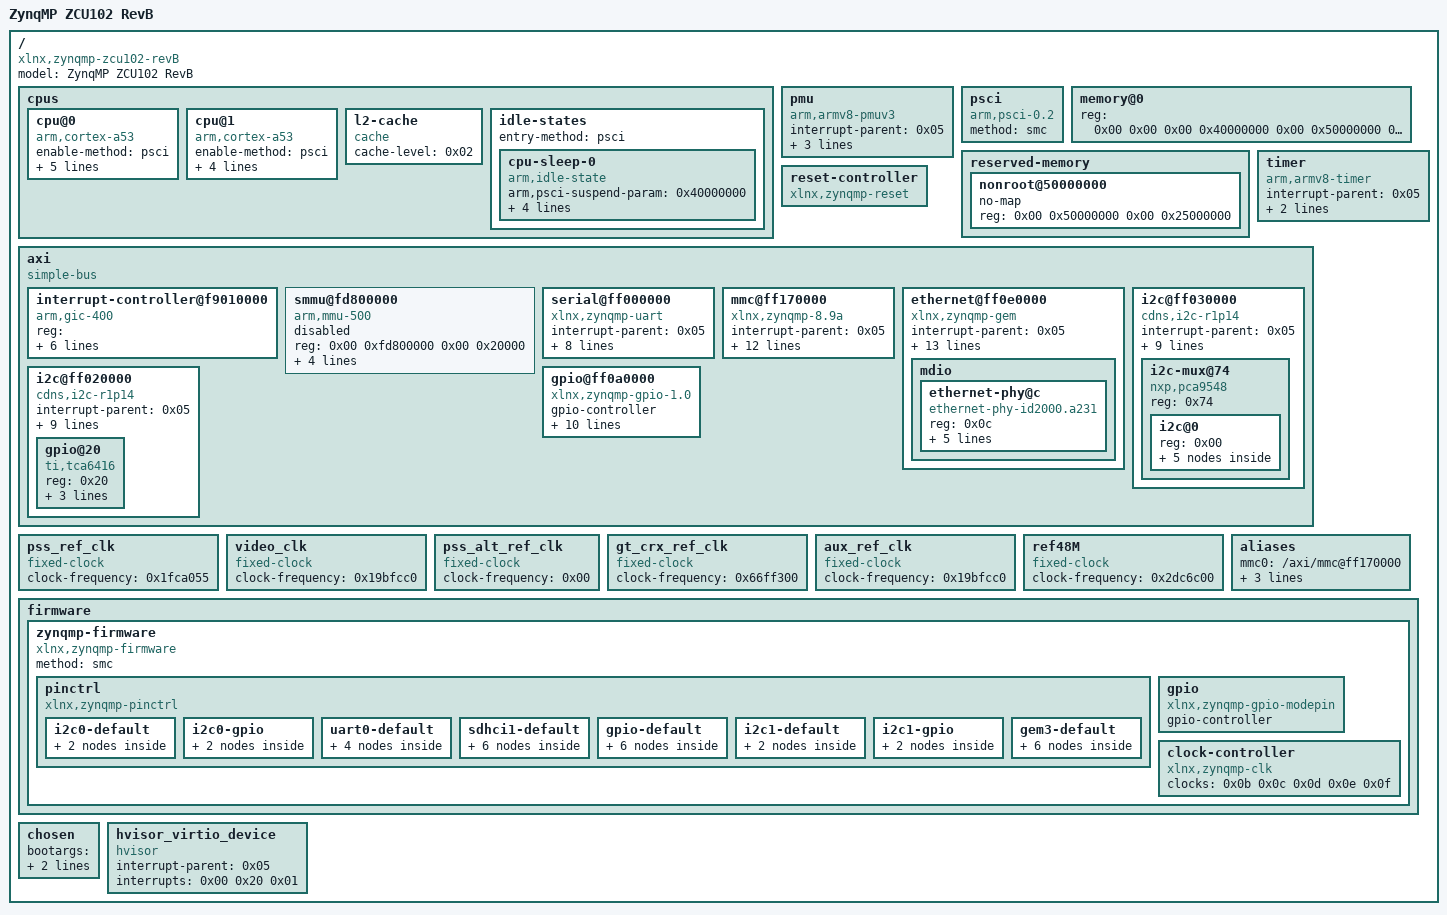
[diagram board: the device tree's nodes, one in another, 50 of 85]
/dts-v1/;

/ {
	compatible = "xlnx,zynqmp-zcu102-revB\0xlnx,zynqmp-zcu102\0xlnx,zynqmp";
	#address-cells = <0x02>;
	#size-cells = <0x02>;
	model = "ZynqMP ZCU102 RevB";

    cpus {
		#address-cells = <0x01>;
		#size-cells = <0x00>;

		cpu@0 {
			compatible = "arm,cortex-a53";
			device_type = "cpu";
			enable-method = "psci";
			operating-points-v2 = <0x01>;
			reg = <0x00>;
			cpu-idle-states = <0x02>;
			next-level-cache = <0x03>;
			clocks = <0x04 0x0a>;
			phandle = <0x06>;
		};

		cpu@1 {
			compatible = "arm,cortex-a53";
			device_type = "cpu";
			enable-method = "psci";
			reg = <0x01>;
			operating-points-v2 = <0x01>;
			cpu-idle-states = <0x02>;
			next-level-cache = <0x03>;
			phandle = <0x07>;
		};

		l2-cache {
			compatible = "cache";
			cache-level = <0x02>;
			phandle = <0x03>;
		};

		idle-states {
			entry-method = "psci";

			cpu-sleep-0 {
				compatible = "arm,idle-state";
				arm,psci-suspend-param = <0x40000000>;
				local-timer-stop;
				entry-latency-us = <0x12c>;
				exit-latency-us = <0x258>;
				min-residency-us = <0x2710>;
				phandle = <0x02>;
			};
		};
	};

	pmu {
		compatible = "arm,armv8-pmuv3";
		interrupt-parent = <0x05>;
		interrupts = <0x00 0x8f 0x04 0x00 0x90 0x04 0x00 0x91 0x04 0x00 0x92 0x04>;
		interrupt-affinity = <0x06 0x07 0x08 0x09>;
	};

	psci {
		compatible = "arm,psci-0.2";
		method = "smc";
	};

    memory@0 {
		device_type = "memory";
		reg = <0x00 0x00 0x00 0x40000000 0x00 0x50000000 0x00 0x25000000>;
	};

	reserved-memory {
		#address-cells = <0x02>;
		#size-cells = <0x02>;
		ranges;
		nonroot@50000000 {
			no-map;
			reg = <0x00 0x50000000 0x00 0x25000000>;
		};
	};

    timer {
		compatible = "arm,armv8-timer";
		interrupt-parent = <0x05>;
		interrupts = <0x01 0x0d 0xf08 0x01 0x0e 0xf08 0x01 0x0b 0xf08 0x01 0x0a 0xf08>;
	};

    reset-controller {
			compatible = "xlnx,zynqmp-reset";
			#reset-cells = <0x01>;
			phandle = <0x11>;
	};


    axi {
		compatible = "simple-bus";
		bootph-all;
		#address-cells = <0x02>;
		#size-cells = <0x02>;
		ranges;
		phandle = <0x58>;

		interrupt-controller@f9010000 {
			compatible = "arm,gic-400";
			#interrupt-cells = <0x03>;
			reg = <0x00 0xf9010000 0x00 0x10000 0x00 0xf9020000 0x00 0x20000 0x00 0xf9040000 0x00 0x20000 0x00 0xf9060000 0x00 0x20000>;
			interrupt-controller;
			interrupt-parent = <0x05>;
			interrupts = <0x01 0x09 0xf04>;
			num_cpus = <0x02>;
			num_interrupts = <0x60>;
			phandle = <0x05>;
		};

		smmu@fd800000 {
			compatible = "arm,mmu-500";
			reg = <0x00 0xfd800000 0x00 0x20000>;
			#iommu-cells = <0x01>;
			status = "disabled";
			#global-interrupts = <0x01>;
			interrupt-parent = <0x05>;
			interrupts = <0x00 0x9b 0x04 0x00 0x9b 0x04 0x00 0x9b 0x04 0x00 0x9b 0x04 0x00 0x9b 0x04 0x00 0x9b 0x04 0x00 0x9b 0x04 0x00 0x9b 0x04 0x00 0x9b 0x04 0x00 0x9b 0x04 0x00 0x9b 0x04 0x00 0x9b 0x04 0x00 0x9b 0x04 0x00 0x9b 0x04 0x00 0x9b 0x04 0x00 0x9b 0x04 0x00 0x9b 0x04>;
			phandle = <0x14>;
		};


        serial@ff000000 {
			bootph-all;
			compatible = "xlnx,zynqmp-uart\0cdns,uart-r1p12";
			status = "okay";
			interrupt-parent = <0x05>;
			interrupts = <0x00 0x15 0x04>;
			reg = <0x00 0xff000000 0x00 0x1000>;
			clock-names = "uart_clk\0pclk";
			power-domains = <0x12 0x21>;
			clocks = <0x04 0x38 0x04 0x1f>;
			pinctrl-names = "default";
			pinctrl-0 = <0x25>;
			cts-override;
			device_type = "serial";
			port-number = <0x00>;
			u-boot,dm-pre-reloc;
			phandle = <0x95>;
		};


        mmc@ff170000 {
			bootph-all;
			compatible = "xlnx,zynqmp-8.9a\0arasan,sdhci-8.9a";
			status = "okay";
			interrupt-parent = <0x05>;
			interrupts = <0x00 0x31 0x04>;
			reg = <0x00 0xff170000 0x00 0x1000>;
			clock-names = "clk_xin\0clk_ahb";
			iommus = <0x14 0x871>;
			power-domains = <0x12 0x28>;
			#clock-cells = <0x01>;
			clock-output-names = "clk_out_sd1\0clk_in_sd1";
			resets = <0x11 0x27>;
			clocks = <0x04 0x37 0x04 0x1f>;
			assigned-clocks = <0x04 0x37>;
			no-1-8-v;
			pinctrl-names = "default";
			pinctrl-0 = <0x24>;
			clock-frequency = <0xa98a581>;
			xlnx,mio-bank = <0x01>;
			phandle = <0x8e>;
		};

		ethernet@ff0e0000 {
			compatible = "xlnx,zynqmp-gem\0cdns,gem";
			status = "okay";
			interrupt-parent = <0x05>;
			interrupts = <0x00 0x3f 0x04 0x00 0x3f 0x04>;
			reg = <0x00 0xff0e0000 0x00 0x1000>;
			clock-names = "pclk\0hclk\0tx_clk\0rx_clk\0tsu_clk";
			#address-cells = <0x01>;
			#size-cells = <0x00>;
			iommus = <0x14 0x877>;
			power-domains = <0x12 0x20>;
			resets = <0x11 0x20>;
			reset-names = "gem3_rst";
			clocks = <0x04 0x1f 0x04 0x6b 0x04 0x30 0x04 0x34 0x04 0x2c>;
			assigned-clocks = <0x04 0x2c>;
			phy-handle = <0x15>;
			pinctrl-names = "default";
			pinctrl-0 = <0x16>;
			phy-mode = "rgmii-id";
			xlnx,ptp-enet-clock = <0x00>;
			local-mac-address = [ff ff ff ff ff ff];
			phandle = <0x74>;

			mdio {
				#address-cells = <0x01>;
				#size-cells = <0x00>;
				phandle = <0x75>;

				ethernet-phy@c {
					#phy-cells = <0x01>;
					compatible = "ethernet-phy-id2000.a231";
					reg = <0x0c>;
					ti,rx-internal-delay = <0x08>;
					ti,tx-internal-delay = <0x0a>;
					ti,fifo-depth = <0x01>;
					ti,dp83867-rxctrl-strap-quirk;
					reset-gpios = <0x17 0x06 0x01>;
					phandle = <0x15>;
				};
			};
		};
		

		i2c@ff030000 {
			compatible = "cdns,i2c-r1p14";
			status = "okay";
			interrupt-parent = <0x05>;
			interrupts = <0x00 0x12 0x04>;
			clock-frequency = <0x61a80>;
			reg = <0x00 0xff030000 0x00 0x1000>;
			#address-cells = <0x01>;
			#size-cells = <0x00>;
			power-domains = <0x12 0x26>;
			clocks = <0x04 0x3e>;
			pinctrl-names = "default\0gpio";
			pinctrl-0 = <0x1c>;
			pinctrl-1 = <0x1d>;
			scl-gpios = <0x1b 0x10 0x06>;
			sda-gpios = <0x1b 0x11 0x06>;
			phandle = <0x78>;

			i2c-mux@74 {
				compatible = "nxp,pca9548";
				#address-cells = <0x01>;
				#size-cells = <0x00>;
				reg = <0x74>;

				i2c@0 {
					#address-cells = <0x01>;
					#size-cells = <0x00>;
					reg = <0x00>;

					eeprom@54 {
						compatible = "atmel,24c08";
						reg = <0x54>;
						#address-cells = <0x01>;
						#size-cells = <0x01>;
						phandle = <0x79>;

						board-sn@0 {
							reg = <0x00 0x14>;
							phandle = <0x7a>;
						};

						eth-mac@20 {
							reg = <0x20 0x06>;
							phandle = <0x7b>;
						};

						board-name@d0 {
							reg = <0xd0 0x06>;
							phandle = <0x7c>;
						};

						board-revision@e0 {
							reg = <0xe0 0x03>;
							phandle = <0x7d>;
						};
					};
				};
			};
		};


		i2c@ff020000 {
			compatible = "cdns,i2c-r1p14";
			status = "okay";
			interrupt-parent = <0x05>;
			interrupts = <0x00 0x11 0x04>;
			clock-frequency = <0x61a80>;
			reg = <0x00 0xff020000 0x00 0x1000>;
			#address-cells = <0x01>;
			#size-cells = <0x00>;
			power-domains = <0x12 0x25>;
			clocks = <0x04 0x3d>;
			pinctrl-names = "default\0gpio";
			pinctrl-0 = <0x19>;
			pinctrl-1 = <0x1a>;
			scl-gpios = <0x1b 0x0e 0x06>;
			sda-gpios = <0x1b 0x0f 0x06>;
			phandle = <0x76>;

			gpio@20 {
				compatible = "ti,tca6416";
				reg = <0x20>;
				gpio-controller;
				#gpio-cells = <0x02>;
				gpio-line-names = "PS_GTR_LAN_SEL0\0PS_GTR_LAN_SEL1\0PS_GTR_LAN_SEL2\0PS_GTR_LAN_SEL3\0PCI_CLK_DIR_SEL\0IIC_MUX_RESET_B\0GEM3_EXP_RESET_B\0\0\0\0\0\0\0\0\0";
				phandle = <0x17>;
			};
		};


		gpio@ff0a0000 {
			compatible = "xlnx,zynqmp-gpio-1.0";
			status = "okay";
			#gpio-cells = <0x02>;
			gpio-controller;
			interrupt-parent = <0x05>;
			interrupts = <0x00 0x10 0x04>;
			interrupt-controller;
			#interrupt-cells = <0x02>;
			reg = <0x00 0xff0a0000 0x00 0x1000>;
			power-domains = <0x12 0x2e>;
			clocks = <0x04 0x1f>;
			pinctrl-names = "default";
			pinctrl-0 = <0x18>;
			emio-gpio-width = <0x20>;
			gpio-mask-high = <0x00>;
			gpio-mask-low = <0x5600>;
			phandle = <0x1b>;
		};
    };

    pss_ref_clk {
		bootph-all;
		compatible = "fixed-clock";
		#clock-cells = <0x00>;
		clock-frequency = <0x1fca055>;
		phandle = <0x0b>;
	};

	video_clk {
		bootph-all;
		compatible = "fixed-clock";
		#clock-cells = <0x00>;
		clock-frequency = <0x19bfcc0>;
		phandle = <0x0c>;
	};

	pss_alt_ref_clk {
		bootph-all;
		compatible = "fixed-clock";
		#clock-cells = <0x00>;
		clock-frequency = <0x00>;
		phandle = <0x0d>;
	};

	gt_crx_ref_clk {
		bootph-all;
		compatible = "fixed-clock";
		#clock-cells = <0x00>;
		clock-frequency = <0x66ff300>;
		phandle = <0x0f>;
	};

	aux_ref_clk {
		bootph-all;
		compatible = "fixed-clock";
		#clock-cells = <0x00>;
		clock-frequency = <0x19bfcc0>;
		phandle = <0x0e>;
	};

	ref48M {
		compatible = "fixed-clock";
		#clock-cells = <0x00>;
		clock-frequency = <0x2dc6c00>;
		phandle = <0x1e>;
	};

    aliases {
		mmc0 = "/axi/mmc@ff170000";
		serial0 = "/axi/serial@ff000000";
		ethernet0 = "/axi/ethernet@ff0e0000";
		i2c1 = "/axi/i2c@ff030000";
	};

    firmware {

		zynqmp-firmware {
			compatible = "xlnx,zynqmp-firmware";
			bootph-all;
			method = "smc";
			#power-domain-cells = <0x01>;
			phandle = <0x12>;

            pinctrl {
				compatible = "xlnx,zynqmp-pinctrl";
				status = "okay";
				phandle = <0x56>;

				i2c0-default {
					phandle = <0x19>;

					mux {
						groups = "i2c0_3_grp";
						function = "i2c0";
					};

					conf {
						groups = "i2c0_3_grp";
						bias-pull-up;
						slew-rate = <0x01>;
						power-source = <0x01>;
					};
				};

				i2c0-gpio {
					phandle = <0x1a>;

					mux {
						groups = "gpio0_14_grp\0gpio0_15_grp";
						function = "gpio0";
					};

					conf {
						groups = "gpio0_14_grp\0gpio0_15_grp";
						slew-rate = <0x01>;
						power-source = <0x01>;
					};
				};

				uart0-default {
					phandle = <0x25>;

					mux {
						groups = "uart0_4_grp";
						function = "uart0";
					};

					conf {
						groups = "uart0_4_grp";
						slew-rate = <0x01>;
						power-source = <0x01>;
					};

					conf-rx {
						pins = "MIO18";
						bias-high-impedance;
					};

					conf-tx {
						pins = "MIO19";
						bias-disable;
					};
				};

				sdhci1-default {
					phandle = <0x24>;

					mux {
						groups = "sdio1_0_grp";
						function = "sdio1";
					};

					conf {
						groups = "sdio1_0_grp";
						slew-rate = <0x01>;
						power-source = <0x01>;
						bias-disable;
					};

					mux-cd {
						groups = "sdio1_cd_0_grp";
						function = "sdio1_cd";
					};

					conf-cd {
						groups = "sdio1_cd_0_grp";
						bias-high-impedance;
						bias-pull-up;
						slew-rate = <0x01>;
						power-source = <0x01>;
					};

					mux-wp {
						groups = "sdio1_wp_0_grp";
						function = "sdio1_wp";
					};

					conf-wp {
						groups = "sdio1_wp_0_grp";
						bias-high-impedance;
						bias-pull-up;
						slew-rate = <0x01>;
						power-source = <0x01>;
					};
				};

				gpio-default {
					phandle = <0x18>;

					mux-sw {
						function = "gpio0";
						groups = "gpio0_22_grp\0gpio0_23_grp";
					};

					conf-sw {
						groups = "gpio0_22_grp\0gpio0_23_grp";
						slew-rate = <0x01>;
						power-source = <0x01>;
					};

					mux-msp {
						function = "gpio0";
						groups = "gpio0_13_grp\0gpio0_38_grp";
					};

					conf-msp {
						groups = "gpio0_13_grp\0gpio0_38_grp";
						slew-rate = <0x01>;
						power-source = <0x01>;
					};

					conf-pull-up {
						pins = "MIO22\0MIO23";
						bias-pull-up;
					};

					conf-pull-none {
						pins = "MIO13\0MIO38";
						bias-disable;
					};
				};

				i2c1-default {
					phandle = <0x1c>;

					mux {
						groups = "i2c1_4_grp";
						function = "i2c1";
					};

					conf {
						groups = "i2c1_4_grp";
						bias-pull-up;
						slew-rate = <0x01>;
						power-source = <0x01>;
					};
				};

				i2c1-gpio {
					phandle = <0x1d>;

					mux {
						groups = "gpio0_16_grp\0gpio0_17_grp";
						function = "gpio0";
					};

					conf {
						groups = "gpio0_16_grp\0gpio0_17_grp";
						slew-rate = <0x01>;
						power-source = <0x01>;
					};
				};

				gem3-default {
					phandle = <0x16>;

					mux {
						function = "ethernet3";
						groups = "ethernet3_0_grp";
					};

					conf {
						groups = "ethernet3_0_grp";
						slew-rate = <0x01>;
						power-source = <0x01>;
					};

					conf-rx {
						pins = "MIO70\0MIO71\0MIO72\0MIO73\0MIO74\0MIO75";
						bias-high-impedance;
						low-power-disable;
					};

					conf-tx {
						pins = "MIO64\0MIO65\0MIO66\0MIO67\0MIO68\0MIO69";
						bias-disable;
						low-power-enable;
					};

					mux-mdio {
						function = "mdio3";
						groups = "mdio3_0_grp";
					};

					conf-mdio {
						groups = "mdio3_0_grp";
						slew-rate = <0x01>;
						power-source = <0x01>;
						bias-disable;
					};
				};
			};

			gpio {
				compatible = "xlnx,zynqmp-gpio-modepin";
				gpio-controller;
				#gpio-cells = <0x02>;
				phandle = <0x27>;
			};

			clock-controller {
				bootph-all;
				#clock-cells = <0x01>;
				compatible = "xlnx,zynqmp-clk";
				clocks = <0x0b 0x0c 0x0d 0x0e 0x0f>;
				clock-names = "pss_ref_clk\0video_clk\0pss_alt_ref_clk\0aux_ref_clk\0gt_crx_ref_clk";
				phandle = <0x04>;
			};
		};
	};

    chosen {
		bootargs = "earlycon console=ttyPS0,115200 root=/dev/mmcblk0p2 rootwait rw";
		stdout-path = "serial0:115200n8";
	};

	hvisor_virtio_device {
		compatible = "hvisor";
		interrupt-parent = <0x05>;
		interrupts = <0x00 0x20 0x01>;
	};

	
};
